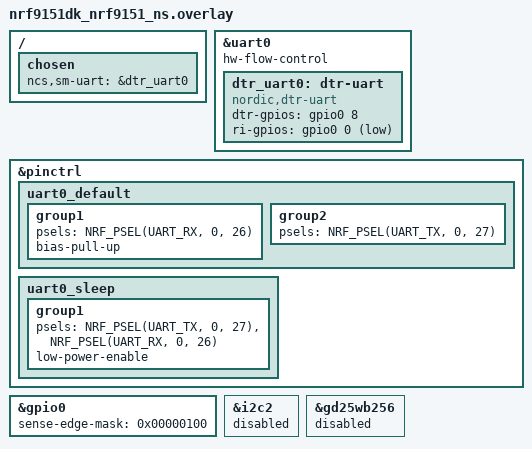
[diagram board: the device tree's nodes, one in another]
/*
 * Copyright (c) 2024 Nordic Semiconductor ASA
 *
 * SPDX-License-Identifier: LicenseRef-Nordic-5-Clause
 */

/ {
	chosen {
		ncs,sm-uart = &dtr_uart0;
	};
};

/* DTR with DK */
&uart0 {
	status = "okay";
	hw-flow-control;

	dtr_uart0: dtr-uart {
		compatible = "nordic,dtr-uart";
		dtr-gpios = <&gpio0 8 (GPIO_PULL_UP | GPIO_ACTIVE_HIGH)>;
		ri-gpios = <&gpio0 0 GPIO_ACTIVE_LOW>;
		status = "okay";
	};
};

&pinctrl {
	uart0_default: uart0_default {
		group1 {
			psels = <NRF_PSEL(UART_RX, 0, 26)>;
			bias-pull-up;
		};
		group2 {
			psels = <NRF_PSEL(UART_TX, 0, 27)>;
		};
	};

	uart0_sleep: uart0_sleep {
		group1 {
			psels = <NRF_PSEL(UART_TX, 0, 27)>,
					<NRF_PSEL(UART_RX, 0, 26)>;
			low-power-enable;
		};
	};
};

&gpio0 {
	status = "okay";
	/* Use PORT event for DTR (8) pin to save power */
	sense-edge-mask = <0x00000100>;
};

&i2c2 {
	status = "disabled";
};

/* Disable external flash */
&gd25wb256 {
	status = "disabled";
};
